# MCXA153 register map
Vendor: nxp.com; File version: 1.0
CPU: CM33 r2p0, little endian, no MPU, no FPU, VTOR, 3 interrupt priority bits
Registers are 32-bit, read-write, reset 0x0 unless marked. A register's access mark holds for its fields unless they carry their own. Offsets are from the block's base; [hi:lo] are bit positions; {n}, {i} and the like mark numbered series; 'fields as' and 'values as' point back to an identical list.

## WUU0 — WUU
Base 0x40092000
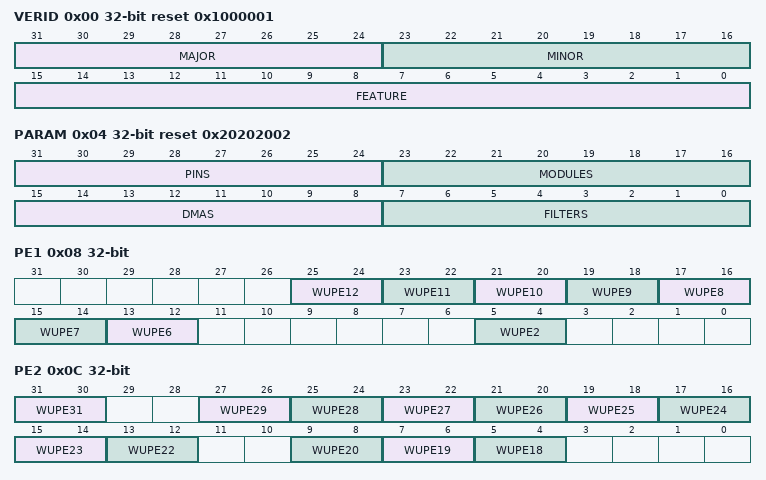
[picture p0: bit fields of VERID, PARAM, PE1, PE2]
0x00 VERID ro reset 0x1000001 — Version ID
  [31:24] MAJOR — Major Version Number
  [23:16] MINOR — Minor Version Number
  [15:0] FEATURE — Feature Specification Number
    0=STANDARD (Standard features implemented); 1=FILT_ALL_PWR (Support for DMA/Trigger generation from wake-up pins and filters enabled. Support for external pin/filter detection during all power modes enabled.)
0x04 PARAM ro reset 0x20202002 — Parameter
  [31:24] PINS — Pin Number
  [23:16] MODULES — Module Number
  [15:8] DMAS — DMA Number
  [7:0] FILTERS — Filter Number
0x08 PE1 — Pin Enable 1
  [all] fields
    0=DISABLE; 1=EN_RISE_HI (Enable (detect on rising edge or high level)); 2=EN_FALL_LO (Enable (detect on falling edge or low level)); 3=EN_ANY (Enable (detect on any edge))
  [2n+1:2n] WUPE{n} (n=6..12) — Wake-up Pin Enable for WUU_Pn
  [5:4] WUPE2 — Wake-up Pin Enable for WUU_Pn
0x0C PE2 — Pin Enable 2
  [all] fields
    values as the fields of PE1
  [31:30] WUPE31 — Wake-up Pin Enable for WUU_Pn
  [2n-31:2n-32] WUPE{n} (n=22..29) — Wake-up Pin Enable for WUU_Pn
  [9:8] WUPE20 — Wake-up Pin Enable for WUU_Pn
  [7:6] WUPE19 — Wake-up Pin Enable for WUU_Pn
  [5:4] WUPE18 — Wake-up Pin Enable for WUU_Pn
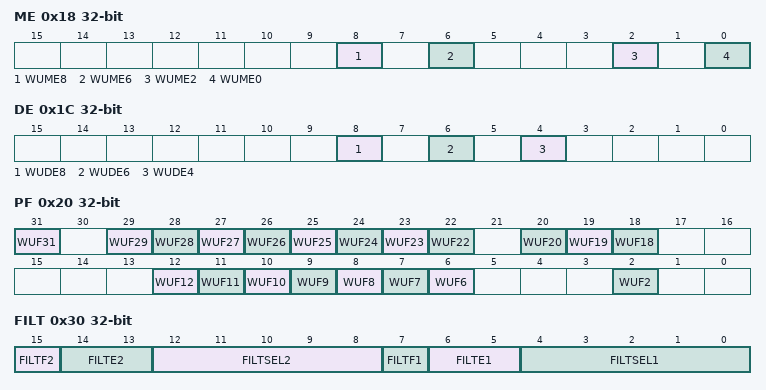
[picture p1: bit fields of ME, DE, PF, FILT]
0x18 ME — Module Interrupt Enable
  [8] WUME8 — Module Interrupt Wake-up Enable for Module 8
  [6] WUME6 — Module Interrupt Wake-up Enable for Module 6
  [2] WUME2 — Module Interrupt Wake-up Enable for Module 2
  [0] WUME0 — Module Interrupt Wake-up Enable for Module 0
0x1C DE — Module DMA/Trigger Enable
  [8] WUDE8 — DMA/Trigger Wake-up Enable for Module 8
  [6] WUDE6 — DMA/Trigger Wake-up Enable for Module 6
  [4] WUDE4 — DMA/Trigger Wake-up Enable for Module 4
0x20 PF — Pin Flag
  [all] fields
    0=NO_FLAG; 1=FLAG (Yes)
  [31] WUF31 write-1-clears — Wake-up Flag for WUU_Pn
  [n] WUF{n} write-1-clears (n=22..29) — Wake-up Flag for WUU_Pn
  [20] WUF20 write-1-clears — Wake-up Flag for WUU_Pn
  [19] WUF19 write-1-clears — Wake-up Flag for WUU_Pn
  [18] WUF18 write-1-clears — Wake-up Flag for WUU_Pn
  [n] WUF{n} write-1-clears (n=6..12) — Wake-up Flag for WUU_Pn
  [2] WUF2 write-1-clears — Wake-up Flag for WUU_Pn
0x30 FILT — Pin Filter
  [15] FILTF2 write-1-clears — Filter 2 Flag
    0=NO_FLAG; 1=FLAG (Yes)
  [14:13] FILTE2 — Filter 2 Enable
    0=DISABLE; 1=EN_RISE_HI (Enable (Detect on rising edge or high level)); 2=EN_FALL_LO (Enable (Detect on falling edge or low level)); 3=EN_ANY (Enable (Detect on any edge))
  [12:8] FILTSEL2 — Filter 2 Pin Select
  [7] FILTF1 write-1-clears — Filter 1 Flag
    0=NO_FLAG; 1=FLAG (Yes)
  [6:5] FILTE1 — Filter 1 Enable
    values as FILTE2
  [4:0] FILTSEL1 — Filter 1 Pin Select
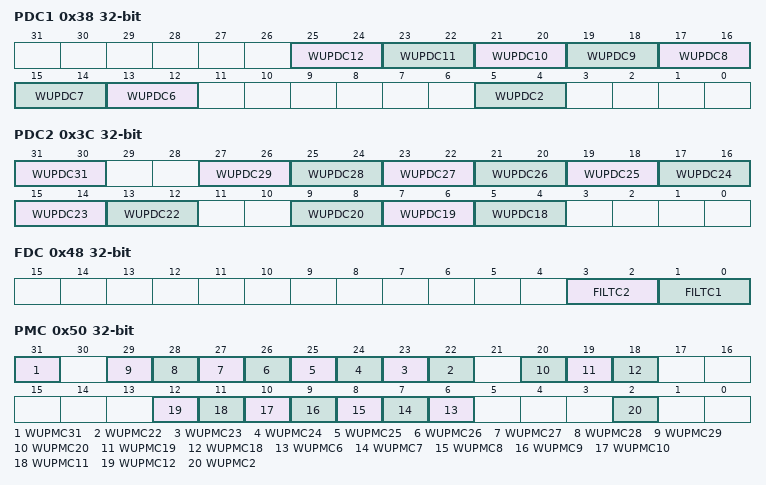
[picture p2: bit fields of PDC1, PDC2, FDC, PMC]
0x38 PDC1 — Pin DMA/Trigger Configuration 1
  [all] fields
    0=INTERRUPT; 1=DMA_REQ (DMA request); 2=TRIGGER (Trigger event)
  [2n+1:2n] WUPDC{n} (n=6..12) — Wake-up Pin Configuration for WUU_Pn
  [5:4] WUPDC2 — Wake-up Pin Configuration for WUU_Pn
0x3C PDC2 — Pin DMA/Trigger Configuration 2
  [all] fields
    values as the fields of PDC1
  [31:30] WUPDC31 — Wake-up Pin Configuration for WUU_Pn
  [2n-31:2n-32] WUPDC{n} (n=22..29) — Wake-up Pin Configuration for WUU_Pn
  [9:8] WUPDC20 — Wake-up Pin Configuration for WUU_Pn
  [7:6] WUPDC19 — Wake-up Pin Configuration for WUU_Pn
  [5:4] WUPDC18 — Wake-up Pin Configuration for WUU_Pn
0x48 FDC — Pin Filter DMA/Trigger Configuration
  [3:2] FILTC2 — Filter Configuration for FILTn
    values as the fields of PDC1
  [1:0] FILTC1 — Filter Configuration for FILTn
    values as the fields of PDC1
0x50 PMC — Pin Mode Configuration
  [all] fields
    0=LOW_PWR_ONLY (Active only during a low-leakage mode. You can modify the corresponding fields within Pin Enable (PEn) or Pin DMA/Trigger Configuration (PDCn).); 1=ANY_PWR (Active during all power modes. Do not modify the corresponding fields within Pin Enable (PEn) or Pin DMA/Trigger Configuration (PDCn).)
  [31] WUPMC31 — Wake-up Pin Mode Configuration for WUU_Pn
  [n] WUPMC{n} (n=22..29) — Wake-up Pin Mode Configuration for WUU_Pn
  [20] WUPMC20 — Wake-up Pin Mode Configuration for WUU_Pn
  [19] WUPMC19 — Wake-up Pin Mode Configuration for WUU_Pn
  [18] WUPMC18 — Wake-up Pin Mode Configuration for WUU_Pn
  [n] WUPMC{n} (n=6..12) — Wake-up Pin Mode Configuration for WUU_Pn
  [2] WUPMC2 — Wake-up Pin Mode Configuration for WUU_Pn
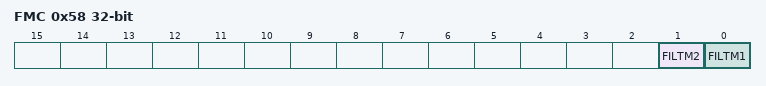
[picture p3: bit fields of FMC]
0x58 FMC — Pin Filter Mode Configuration
  [1] FILTM2 — Filter Mode for FILTn
    0=LOW_PWR_ONLY (Active only during Power Down/Deep Power Down mode); 1=ANY_PWR (Active during all power modes)
  [0] FILTM1 — Filter Mode for FILTn
    values as FILTM2
